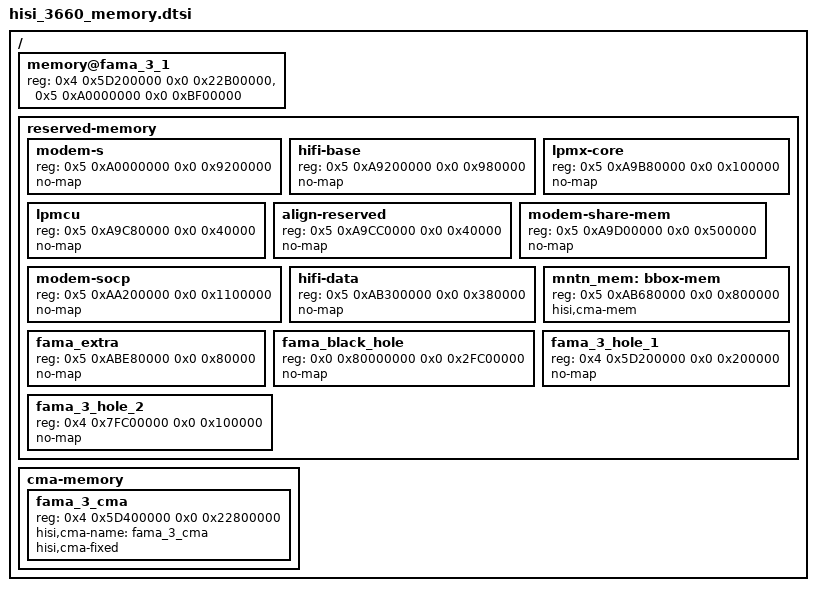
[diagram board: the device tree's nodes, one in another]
/include/ "hisi_3660_memory_common.dtsi"

/{

	memory@fama_3_1 {
		device_type = "memory";
		reg = <0x4 0x5D200000 0x0 0x22B00000>,
		      <0x5 0xA0000000 0x0 0xBF00000 >;
	};

	reserved-memory {
		#address-cells = <2>;
		#size-cells = <2>;
		ranges;

		modem-s {
			reg = <0x5 0xA0000000 0x0 0x9200000>;
			no-map;
		};

		hifi-base {
			reg = <0x5 0xA9200000 0x0 0x980000>;
			no-map;
		};

		lpmx-core {
			reg = <0x5 0xA9B80000 0x0 0x100000>;
			no-map;
		};

		lpmcu {
			reg = <0x5 0xA9C80000 0x0 0x40000>;
			no-map;
		};

		align-reserved {
			reg = <0x5 0xA9CC0000 0x0 0x40000>;
			no-map;
		};

		modem-share-mem {
			reg = <0x5 0xA9D00000 0x0 0x500000>;
			no-map;
		};

		modem-socp {
			reg = <0x5 0xAA200000 0x0 0x1100000>;
			no-map;
		};


		hifi-data {
			reg = <0x5 0xAB300000 0x0 0x380000>;
			no-map;
		};

		mntn_mem:bbox-mem {
			reg = <0x5 0xAB680000 0x0 0x800000>;
			hisi,cma-mem;
		};

		fama_extra {
                        reg = <0x5 0xABE80000 0x0 0x80000>;
			no-map;
                };

		fama_black_hole {
			reg = <0x0 0x80000000 0x0 0x2FC00000>;
			no-map;
		};

		fama_3_hole_1 {
			reg = <0x4 0x5D200000 0x0 0x200000>;
			no-map;
		};


		fama_3_hole_2 {
			reg = <0x4 0x7FC00000 0x0 0x100000>;
			no-map;
		};
	};

	cma-memory {
		#address-cells = <2>;
		#size-cells = <2>;
		ranges;

		fama_3_cma {
			reg = <0x4 0x5D400000 0x0 0x22800000>;
			hisi,cma-name = "fama_3_cma";
			hisi,cma-fixed;
			status = "ok";
		};


	};

};
